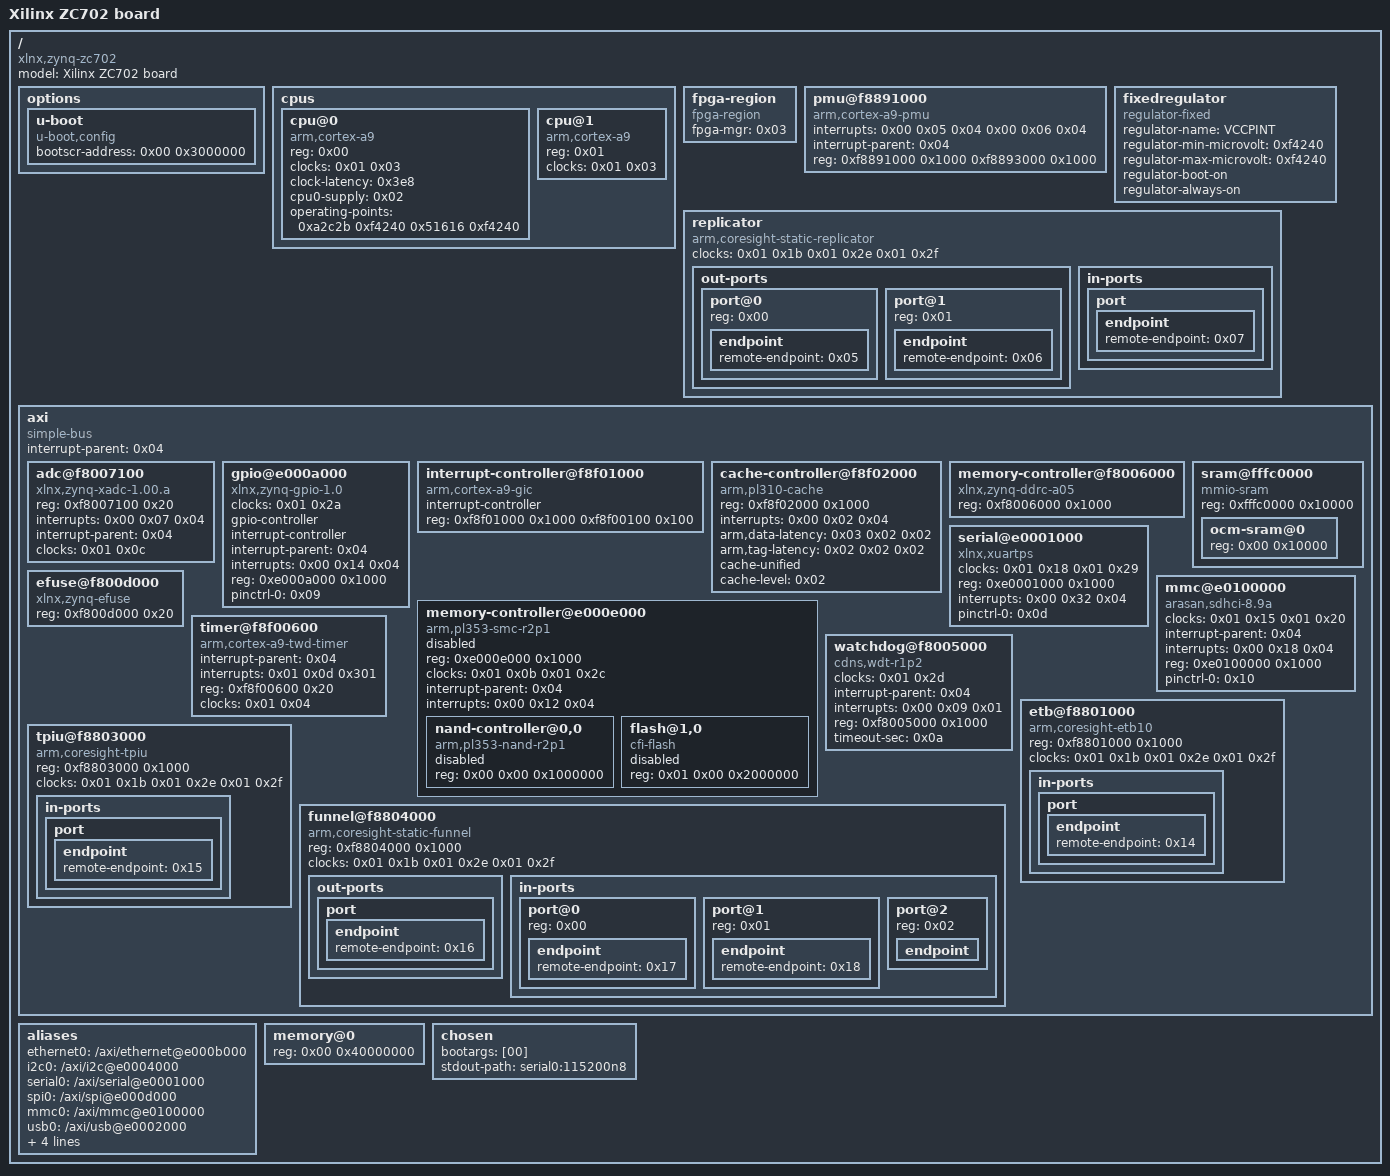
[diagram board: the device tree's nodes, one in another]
/dts-v1/;

/ {
	#address-cells = <0x01>;
	#size-cells = <0x01>;
	compatible = "xlnx,zynq-zc702\0xlnx,zynq-7000";
	model = "Xilinx ZC702 board";

	options {

		u-boot {
			compatible = "u-boot,config";
			bootscr-address = <0x00 0x3000000>;
		};
	};

	cpus {
		#address-cells = <0x01>;
		#size-cells = <0x00>;

		cpu@0 {
			compatible = "arm,cortex-a9";
			device_type = "cpu";
			reg = <0x00>;
			clocks = <0x01 0x03>;
			clock-latency = <0x3e8>;
			cpu0-supply = <0x02>;
			operating-points = <0xa2c2b 0xf4240 0x51616 0xf4240>;
			phandle = <0x19>;
		};

		cpu@1 {
			compatible = "arm,cortex-a9";
			device_type = "cpu";
			reg = <0x01>;
			clocks = <0x01 0x03>;
			phandle = <0x1b>;
		};
	};

	fpga-region {
		compatible = "fpga-region";
		fpga-mgr = <0x03>;
		#address-cells = <0x01>;
		#size-cells = <0x01>;
		ranges;
		phandle = <0x1d>;
	};

	pmu@f8891000 {
		compatible = "arm,cortex-a9-pmu";
		interrupts = <0x00 0x05 0x04 0x00 0x06 0x04>;
		interrupt-parent = <0x04>;
		reg = <0xf8891000 0x1000 0xf8893000 0x1000>;
	};

	fixedregulator {
		compatible = "regulator-fixed";
		regulator-name = "VCCPINT";
		regulator-min-microvolt = <0xf4240>;
		regulator-max-microvolt = <0xf4240>;
		regulator-boot-on;
		regulator-always-on;
		phandle = <0x02>;
	};

	replicator {
		compatible = "arm,coresight-static-replicator";
		clocks = <0x01 0x1b 0x01 0x2e 0x01 0x2f>;
		clock-names = "apb_pclk\0dbg_trc\0dbg_apb";

		out-ports {
			#address-cells = <0x01>;
			#size-cells = <0x00>;

			port@0 {
				reg = <0x00>;

				endpoint {
					remote-endpoint = <0x05>;
					phandle = <0x15>;
				};
			};

			port@1 {
				reg = <0x01>;

				endpoint {
					remote-endpoint = <0x06>;
					phandle = <0x14>;
				};
			};
		};

		in-ports {

			port {

				endpoint {
					remote-endpoint = <0x07>;
					phandle = <0x16>;
				};
			};
		};
	};

	axi {
		bootph-all;
		compatible = "simple-bus";
		#address-cells = <0x01>;
		#size-cells = <0x01>;
		interrupt-parent = <0x04>;
		ranges;
		phandle = <0x1e>;

		adc@f8007100 {
			compatible = "xlnx,zynq-xadc-1.00.a";
			reg = <0xf8007100 0x20>;
			interrupts = <0x00 0x07 0x04>;
			interrupt-parent = <0x04>;
			clocks = <0x01 0x0c>;
			phandle = <0x1f>;
		};

		gpio@e000a000 {
			compatible = "xlnx,zynq-gpio-1.0";
			#gpio-cells = <0x02>;
			clocks = <0x01 0x2a>;
			gpio-controller;
			interrupt-controller;
			#interrupt-cells = <0x02>;
			interrupt-parent = <0x04>;
			interrupts = <0x00 0x14 0x04>;
			reg = <0xe000a000 0x1000>;
			pinctrl-names = "default";
			pinctrl-0 = <0x09>;
			phandle = <0x0c>;
		};

		interrupt-controller@f8f01000 {
			compatible = "arm,cortex-a9-gic";
			#interrupt-cells = <0x03>;
			interrupt-controller;
			reg = <0xf8f01000 0x1000 0xf8f00100 0x100>;
			phandle = <0x04>;
		};

		cache-controller@f8f02000 {
			compatible = "arm,pl310-cache";
			reg = <0xf8f02000 0x1000>;
			interrupts = <0x00 0x02 0x04>;
			arm,data-latency = <0x03 0x02 0x02>;
			arm,tag-latency = <0x02 0x02 0x02>;
			cache-unified;
			cache-level = <0x02>;
			phandle = <0x28>;
		};

		memory-controller@f8006000 {
			compatible = "xlnx,zynq-ddrc-a05";
			reg = <0xf8006000 0x1000>;
			phandle = <0x29>;
		};

		sram@fffc0000 {
			compatible = "mmio-sram";
			reg = <0xfffc0000 0x10000>;
			#address-cells = <0x01>;
			#size-cells = <0x01>;
			ranges = <0x00 0xfffc0000 0x10000>;
			phandle = <0x2a>;

			ocm-sram@0 {
				reg = <0x00 0x10000>;
			};
		};

		serial@e0001000 {
			compatible = "xlnx,xuartps\0cdns,uart-r1p8";
			status = "okay";
			clocks = <0x01 0x18 0x01 0x29>;
			clock-names = "uart_clk\0pclk";
			reg = <0xe0001000 0x1000>;
			interrupts = <0x00 0x32 0x04>;
			bootph-all;
			pinctrl-names = "default";
			pinctrl-0 = <0x0d>;
			phandle = <0x2c>;
		};

		memory-controller@e000e000 {
			compatible = "arm,pl353-smc-r2p1\0arm,primecell";
			reg = <0xe000e000 0x1000>;
			status = "disabled";
			clock-names = "memclk\0apb_pclk";
			clocks = <0x01 0x0b 0x01 0x2c>;
			ranges = <0x00 0x00 0xe1000000 0x1000000 0x01 0x00 0xe2000000 0x2000000 0x02 0x00 0xe4000000 0x2000000>;
			#address-cells = <0x02>;
			#size-cells = <0x01>;
			interrupt-parent = <0x04>;
			interrupts = <0x00 0x12 0x04>;
			phandle = <0x32>;

			nand-controller@0,0 {
				compatible = "arm,pl353-nand-r2p1";
				reg = <0x00 0x00 0x1000000>;
				status = "disabled";
				phandle = <0x33>;
			};

			flash@1,0 {
				status = "disabled";
				compatible = "cfi-flash";
				reg = <0x01 0x00 0x2000000>;
				phandle = <0x34>;
			};
		};

		mmc@e0100000 {
			compatible = "arasan,sdhci-8.9a";
			status = "okay";
			clock-names = "clk_xin\0clk_ahb";
			clocks = <0x01 0x15 0x01 0x20>;
			interrupt-parent = <0x04>;
			interrupts = <0x00 0x18 0x04>;
			reg = <0xe0100000 0x1000>;
			bootph-all;
			pinctrl-names = "default";
			pinctrl-0 = <0x10>;
			phandle = <0x35>;
		};

/*
		slcr@f8000000 {
			bootph-all;
			#address-cells = <0x01>;
			#size-cells = <0x01>;
			compatible = "xlnx,zynq-slcr\0syscon\0simple-mfd";
			reg = <0xf8000000 0x1000>;
			ranges;
			phandle = <0x11>;

			clkc@100 {
				bootph-all;
				#clock-cells = <0x01>;
				compatible = "xlnx,ps7-clkc";
				fclk-enable = <0x0f>;
				clock-output-names = "armpll\0ddrpll\0iopll\0cpu_6or4x\0cpu_3or2x\0cpu_2x\0cpu_1x\0ddr2x\0ddr3x\0dci\0lqspi\0smc\0pcap\0gem0\0gem1\0fclk0\0fclk1\0fclk2\0fclk3\0can0\0can1\0sdio0\0sdio1\0uart0\0uart1\0spi0\0spi1\0dma\0usb0_aper\0usb1_aper\0gem0_aper\0gem1_aper\0sdio0_aper\0sdio1_aper\0spi0_aper\0spi1_aper\0can0_aper\0can1_aper\0i2c0_aper\0i2c1_aper\0uart0_aper\0uart1_aper\0gpio_aper\0lqspi_aper\0smc_aper\0swdt\0dbg_trc\0dbg_apb";
				reg = <0x100 0x100>;
				ps-clk-frequency = <0x1fca055>;
				phandle = <0x01>;
			};

			rstc@200 {
				compatible = "xlnx,zynq-reset";
				reg = <0x200 0x48>;
				#reset-cells = <0x01>;
				syscon = <0x11>;
				phandle = <0x37>;
			};

			pinctrl@700 {
				compatible = "xlnx,pinctrl-zynq";
				reg = <0x700 0x200>;
				syscon = <0x11>;
				phandle = <0x38>;

				can0-default {
					phandle = <0x08>;

					mux {
						function = "can0";
						groups = "can0_9_grp";
					};

					conf {
						groups = "can0_9_grp";
						slew-rate = <0x00>;
						power-source = <0x01>;
					};

					conf-rx {
						pins = "MIO46";
						bias-high-impedance;
					};

					conf-tx {
						pins = "MIO47";
						bias-disable;
					};
				};

				gem0-default {
					phandle = <0x0f>;

					mux {
						function = "ethernet0";
						groups = "ethernet0_0_grp";
					};

					conf {
						groups = "ethernet0_0_grp";
						slew-rate = <0x00>;
						power-source = <0x04>;
					};

					conf-rx {
						pins = "MIO22\0MIO23\0MIO24\0MIO25\0MIO26\0MIO27";
						bias-high-impedance;
						low-power-disable;
					};

					conf-tx {
						pins = "MIO16\0MIO17\0MIO18\0MIO19\0MIO20\0MIO21";
						bias-disable;
						low-power-enable;
					};

					mux-mdio {
						function = "mdio0";
						groups = "mdio0_0_grp";
					};

					conf-mdio {
						groups = "mdio0_0_grp";
						slew-rate = <0x00>;
						power-source = <0x01>;
						bias-disable;
					};
				};

				gpio0-default {
					phandle = <0x09>;

					mux {
						function = "gpio0";
						groups = "gpio0_7_grp\0gpio0_8_grp\0gpio0_9_grp\0gpio0_10_grp\0gpio0_11_grp\0gpio0_12_grp\0gpio0_13_grp\0gpio0_14_grp";
					};

					conf {
						groups = "gpio0_7_grp\0gpio0_8_grp\0gpio0_9_grp\0gpio0_10_grp\0gpio0_11_grp\0gpio0_12_grp\0gpio0_13_grp\0gpio0_14_grp";
						slew-rate = <0x00>;
						power-source = <0x01>;
					};

					conf-pull-up {
						pins = "MIO9\0MIO10\0MIO11\0MIO12\0MIO13\0MIO14";
						bias-pull-up;
					};

					conf-pull-none {
						pins = "MIO7\0MIO8";
						bias-disable;
					};
				};

				i2c0-default {
					phandle = <0x0a>;

					mux {
						groups = "i2c0_10_grp";
						function = "i2c0";
					};

					conf {
						groups = "i2c0_10_grp";
						bias-pull-up;
						slew-rate = <0x00>;
						power-source = <0x01>;
					};
				};

				i2c0-gpio-grp {
					phandle = <0x0b>;

					mux {
						groups = "gpio0_50_grp\0gpio0_51_grp";
						function = "gpio0";
					};

					conf {
						groups = "gpio0_50_grp\0gpio0_51_grp";
						slew-rate = <0x00>;
						power-source = <0x01>;
					};
				};

				sdhci0-default {
					phandle = <0x10>;

					mux {
						groups = "sdio0_2_grp";
						function = "sdio0";
					};

					conf {
						groups = "sdio0_2_grp";
						slew-rate = <0x00>;
						power-source = <0x01>;
						bias-disable;
					};

					mux-cd {
						groups = "gpio0_0_grp";
						function = "sdio0_cd";
					};

					conf-cd {
						groups = "gpio0_0_grp";
						bias-high-impedance;
						bias-pull-up;
						slew-rate = <0x00>;
						power-source = <0x01>;
					};

					mux-wp {
						groups = "gpio0_15_grp";
						function = "sdio0_wp";
					};

					conf-wp {
						groups = "gpio0_15_grp";
						bias-high-impedance;
						bias-pull-up;
						slew-rate = <0x00>;
						power-source = <0x01>;
					};
				};

				uart1-default {
					phandle = <0x0d>;

					mux {
						groups = "uart1_10_grp";
						function = "uart1";
					};

					conf {
						groups = "uart1_10_grp";
						slew-rate = <0x00>;
						power-source = <0x01>;
					};

					conf-rx {
						pins = "MIO49";
						bias-high-impedance;
					};

					conf-tx {
						pins = "MIO48";
						bias-disable;
					};
				};

				usb0-default {
					phandle = <0x13>;

					mux {
						groups = "usb0_0_grp";
						function = "usb0";
					};

					conf {
						groups = "usb0_0_grp";
						slew-rate = <0x00>;
						power-source = <0x01>;
					};

					conf-rx {
						pins = "MIO29\0MIO31\0MIO36";
						bias-high-impedance;
					};

					conf-tx {
						pins = "MIO28\0MIO30\0MIO32\0MIO33\0MIO34\0MIO35\0MIO37\0MIO38\0MIO39";
						bias-disable;
					};
				};
			};
		};

		dma-controller@f8003000 {
			compatible = "arm,pl330\0arm,primecell";
			reg = <0xf8003000 0x1000>;
			interrupt-parent = <0x04>;
			interrupts = <0x00 0x0d 0x04 0x00 0x0e 0x04 0x00 0x0f 0x04 0x00 0x10 0x04 0x00 0x11 0x04 0x00 0x28 0x04 0x00 0x29 0x04 0x00 0x2a 0x04 0x00 0x2b 0x04>;
			#dma-cells = <0x01>;
			clocks = <0x01 0x1b>;
			clock-names = "apb_pclk";
			phandle = <0x39>;
		};

		devcfg@f8007000 {
			compatible = "xlnx,zynq-devcfg-1.0";
			reg = <0xf8007000 0x100>;
			interrupt-parent = <0x04>;
			interrupts = <0x00 0x08 0x04>;
			clocks = <0x01 0x0c 0x01 0x0f 0x01 0x10 0x01 0x11 0x01 0x12>;
			clock-names = "ref_clk\0fclk0\0fclk1\0fclk2\0fclk3";
			syscon = <0x11>;
			phandle = <0x03>;
		};
*/
		efuse@f800d000 {
			compatible = "xlnx,zynq-efuse";
			reg = <0xf800d000 0x20>;
			phandle = <0x3a>;
		};
/*
		timer@f8f00200 {
			compatible = "arm,cortex-a9-global-timer";
			reg = <0xf8f00200 0x20>;
			interrupts = <0x01 0x0b 0x301>;
			interrupt-parent = <0x04>;
			clocks = <0x01 0x04>;
			phandle = <0x3b>;
		};

		timer@f8001000 {
			interrupt-parent = <0x04>;
			interrupts = <0x00 0x0a 0x04 0x00 0x0b 0x04 0x00 0x0c 0x04>;
			compatible = "cdns,ttc";
			clocks = <0x01 0x06>;
			reg = <0xf8001000 0x1000>;
			phandle = <0x3c>;
		};

		timer@f8002000 {
			interrupt-parent = <0x04>;
			interrupts = <0x00 0x25 0x04 0x00 0x26 0x04 0x00 0x27 0x04>;
			compatible = "cdns,ttc";
			clocks = <0x01 0x06>;
			reg = <0xf8002000 0x1000>;
			phandle = <0x3d>;
		};
*/
		timer@f8f00600 {
			bootph-all;
			interrupt-parent = <0x04>;
			interrupts = <0x01 0x0d 0x301>;
			compatible = "arm,cortex-a9-twd-timer";
			reg = <0xf8f00600 0x20>;
			clocks = <0x01 0x04>;
			phandle = <0x3e>;
		};

		watchdog@f8005000 {
			clocks = <0x01 0x2d>;
			compatible = "cdns,wdt-r1p2";
			interrupt-parent = <0x04>;
			interrupts = <0x00 0x09 0x01>;
			reg = <0xf8005000 0x1000>;
			timeout-sec = <0x0a>;
			phandle = <0x41>;
		};

		etb@f8801000 {
			compatible = "arm,coresight-etb10\0arm,primecell";
			reg = <0xf8801000 0x1000>;
			clocks = <0x01 0x1b 0x01 0x2e 0x01 0x2f>;
			clock-names = "apb_pclk\0dbg_trc\0dbg_apb";

			in-ports {

				port {

					endpoint {
						remote-endpoint = <0x14>;
						phandle = <0x06>;
					};
				};
			};
		};

		tpiu@f8803000 {
			compatible = "arm,coresight-tpiu\0arm,primecell";
			reg = <0xf8803000 0x1000>;
			clocks = <0x01 0x1b 0x01 0x2e 0x01 0x2f>;
			clock-names = "apb_pclk\0dbg_trc\0dbg_apb";

			in-ports {

				port {

					endpoint {
						remote-endpoint = <0x15>;
						phandle = <0x05>;
					};
				};
			};
		};

		funnel@f8804000 {
			compatible = "arm,coresight-static-funnel\0arm,primecell";
			reg = <0xf8804000 0x1000>;
			clocks = <0x01 0x1b 0x01 0x2e 0x01 0x2f>;
			clock-names = "apb_pclk\0dbg_trc\0dbg_apb";

			out-ports {

				port {

					endpoint {
						remote-endpoint = <0x16>;
						phandle = <0x07>;
					};
				};
			};

			in-ports {
				#address-cells = <0x01>;
				#size-cells = <0x00>;

				port@0 {
					reg = <0x00>;

					endpoint {
						remote-endpoint = <0x17>;
						phandle = <0x1a>;
					};
				};

				port@1 {
					reg = <0x01>;

					endpoint {
						remote-endpoint = <0x18>;
						phandle = <0x1c>;
					};
				};

				port@2 {
					reg = <0x02>;

					endpoint {
						phandle = <0x42>;
					};
				};
			};
		};
	};

	aliases {
		ethernet0 = "/axi/ethernet@e000b000";
		i2c0 = "/axi/i2c@e0004000";
		serial0 = "/axi/serial@e0001000";
		spi0 = "/axi/spi@e000d000";
		mmc0 = "/axi/mmc@e0100000";
		usb0 = "/axi/usb@e0002000";
		nvmem0 = "/axi/i2c@e0004000/i2c-mux@74/i2c@2/eeprom@54";
		rtc0 = "/axi/i2c@e0004000/i2c-mux@74/i2c@4/rtc@51";
	};

	memory@0 {
		device_type = "memory";
		reg = <0x00 0x40000000>;
	};

	chosen {
		bootargs = [00];
		stdout-path = "serial0:115200n8";
	};


	__symbols__ {
		cpu0 = "/cpus/cpu@0";
		cpu1 = "/cpus/cpu@1";
		fpga_full = "/fpga-region";
		regulator_vccpint = "/fixedregulator";
		replicator_out_port0 = "/replicator/out-ports/port@0/endpoint";
		replicator_out_port1 = "/replicator/out-ports/port@1/endpoint";
		replicator_in_port0 = "/replicator/in-ports/port/endpoint";
		amba = "/axi";
		adc = "/axi/adc@f8007100";
		can0 = "/axi/can@e0008000";
		can1 = "/axi/can@e0009000";
		gpio0 = "/axi/gpio@e000a000";
		i2c0 = "/axi/i2c@e0004000";
		si570 = "/axi/i2c@e0004000/i2c-mux@74/i2c@0/clock-generator@5d";
		adv7511 = "/axi/i2c@e0004000/i2c-mux@74/i2c@1/hdmi-tx@39";
		eeprom = "/axi/i2c@e0004000/i2c-mux@74/i2c@2/eeprom@54";
		rtc = "/axi/i2c@e0004000/i2c-mux@74/i2c@4/rtc@51";
		i2c1 = "/axi/i2c@e0005000";
		intc = "/axi/interrupt-controller@f8f01000";
		L2 = "/axi/cache-controller@f8f02000";
		mc = "/axi/memory-controller@f8006000";
		ocm = "/axi/sram@fffc0000";
		uart0 = "/axi/serial@e0000000";
		uart1 = "/axi/serial@e0001000";
		spi0 = "/axi/spi@e0006000";
		spi1 = "/axi/spi@e0007000";
		qspi = "/axi/spi@e000d000";
		gem0 = "/axi/ethernet@e000b000";
		ethernet_phy = "/axi/ethernet@e000b000/ethernet-phy@7";
		gem1 = "/axi/ethernet@e000c000";
		smcc = "/axi/memory-controller@e000e000";
		nfc0 = "/axi/memory-controller@e000e000/nand-controller@0,0";
		nor0 = "/axi/memory-controller@e000e000/flash@1,0";
		sdhci0 = "/axi/mmc@e0100000";
		sdhci1 = "/axi/mmc@e0101000";
		slcr = "/axi/slcr@f8000000";
		clkc = "/axi/slcr@f8000000/clkc@100";
		rstc = "/axi/slcr@f8000000/rstc@200";
		pinctrl0 = "/axi/slcr@f8000000/pinctrl@700";
		pinctrl_can0_default = "/axi/slcr@f8000000/pinctrl@700/can0-default";
		pinctrl_gem0_default = "/axi/slcr@f8000000/pinctrl@700/gem0-default";
		pinctrl_gpio0_default = "/axi/slcr@f8000000/pinctrl@700/gpio0-default";
		pinctrl_i2c0_default = "/axi/slcr@f8000000/pinctrl@700/i2c0-default";
		pinctrl_i2c0_gpio = "/axi/slcr@f8000000/pinctrl@700/i2c0-gpio-grp";
		pinctrl_sdhci0_default = "/axi/slcr@f8000000/pinctrl@700/sdhci0-default";
		pinctrl_uart1_default = "/axi/slcr@f8000000/pinctrl@700/uart1-default";
		pinctrl_usb0_default = "/axi/slcr@f8000000/pinctrl@700/usb0-default";
		dmac_s = "/axi/dma-controller@f8003000";
		devcfg = "/axi/devcfg@f8007000";
		efuse = "/axi/efuse@f800d000";
		global_timer = "/axi/timer@f8f00200";
		ttc0 = "/axi/timer@f8001000";
		ttc1 = "/axi/timer@f8002000";
		scutimer = "/axi/timer@f8f00600";
		usb0 = "/axi/usb@e0002000";
		usb1 = "/axi/usb@e0003000";
		watchdog0 = "/axi/watchdog@f8005000";
		etb_in_port = "/axi/etb@f8801000/in-ports/port/endpoint";
		tpiu_in_port = "/axi/tpiu@f8803000/in-ports/port/endpoint";
		funnel_out_port = "/axi/funnel@f8804000/out-ports/port/endpoint";
		funnel0_in_port0 = "/axi/funnel@f8804000/in-ports/port@0/endpoint";
		funnel0_in_port1 = "/axi/funnel@f8804000/in-ports/port@1/endpoint";
		funnel0_in_port2 = "/axi/funnel@f8804000/in-ports/port@2/endpoint";
		ptm0_out_port = "/axi/ptm@f889c000/out-ports/port/endpoint";
		ptm1_out_port = "/axi/ptm@f889d000/out-ports/port/endpoint";
		usb_phy0 = "/phy0@e0002000";
	};
};
